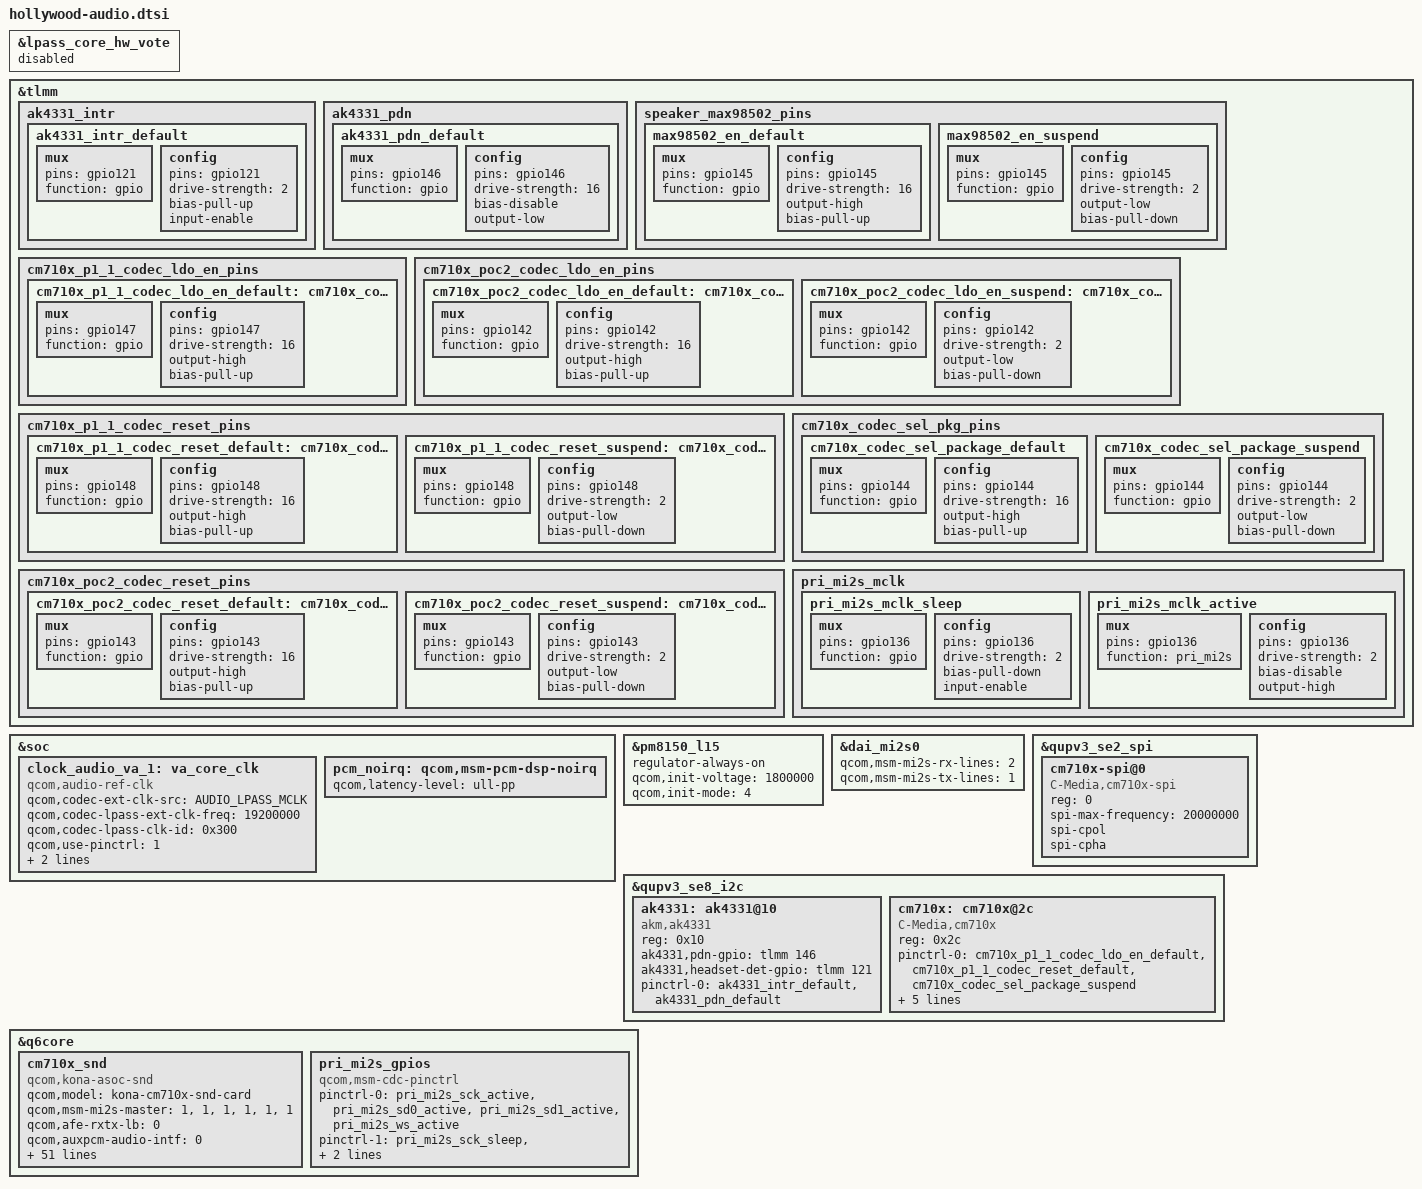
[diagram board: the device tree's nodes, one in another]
#include <dt-bindings/clock/qcom,audio-ext-clk.h>

&lpass_core_hw_vote {
	status = "disabled";
};

&tlmm {
	ak4331_intr {
		ak4331_intr_default: ak4331_intr_default {
			 mux {
				pins = "gpio121";
				function = "gpio";
			};

			config {
				pins = "gpio121";
				drive-strength = <2>; /* 2 mA */
				bias-pull-up; /* pull up */
				input-enable;
			};
		};
	};

	ak4331_pdn {
		ak4331_pdn_default: ak4331_pdn_default {
			 mux {
				pins = "gpio146";
				function = "gpio";
			};

			config {
				pins = "gpio146";
				drive-strength = <16>; /* 16 mA */
				bias-disable; /* no pull */
				output-low;
			};
		};
	};

	speaker_max98502_pins {
		max98502_en_default: max98502_en_default {
			mux {
				pins = "gpio145";
				function = "gpio";
			};

			config {
				pins = "gpio145";
				drive-strength = <16>;
				output-high;
				bias-pull-up;
			};
		};
		max98502_en_suspend: max98502_en_suspend {
			mux {
				pins = "gpio145";
				function = "gpio";
			};

			config {
				pins = "gpio145";
				drive-strength = <2>;
				output-low;
				bias-pull-down;
			};
		};
	};

	cm710x_p1_1_codec_ldo_en_pins {
		cm710x_p1_1_codec_ldo_en_default: cm710x_codec_ldo_en_default {
			mux {
				pins = "gpio147";
				function = "gpio";
			};

			config {
				pins = "gpio147";
				drive-strength = <16>;
				output-high;
				bias-pull-up;
			};
		};
	};

	cm710x_poc2_codec_ldo_en_pins {
		cm710x_poc2_codec_ldo_en_default: cm710x_codec_ldo_en_default {
			mux {
				pins = "gpio142";
				function = "gpio";
			};

			config {
				pins = "gpio142";
				drive-strength = <16>;
				output-high;
				bias-pull-up;
			};
		};
		cm710x_poc2_codec_ldo_en_suspend: cm710x_codec_ldo_en_suspend {
			mux {
				pins = "gpio142";
				function = "gpio";
			};

			config {
				pins = "gpio142";
				drive-strength = <2>;
				output-low;
				bias-pull-down;
			};
		};
	};

	cm710x_p1_1_codec_reset_pins {
		cm710x_p1_1_codec_reset_default: cm710x_codec_reset_default {
			mux {
				pins = "gpio148";
				function = "gpio";
			};

			config {
				pins = "gpio148";
				drive-strength = <16>;
				output-high;
				bias-pull-up;
			};
		};
		cm710x_p1_1_codec_reset_suspend: cm710x_codec_reset_suspend {
			mux {
				pins = "gpio148";
				function = "gpio";
			};

			config {
				pins = "gpio148";
				drive-strength = <2>;
				output-low;
				bias-pull-down;
			};
		};
	};

	cm710x_poc2_codec_reset_pins {
		cm710x_poc2_codec_reset_default: cm710x_codec_reset_default {
			mux {
				pins = "gpio143";
				function = "gpio";
			};

			config {
				pins = "gpio143";
				drive-strength = <16>;
				output-high;
				bias-pull-up;
			};
		};
		cm710x_poc2_codec_reset_suspend: cm710x_codec_reset_suspend {
			mux {
				pins = "gpio143";
				function = "gpio";
			};

			config {
				pins = "gpio143";
				drive-strength = <2>;
				output-low;
				bias-pull-down;
			};
		};
	};

	cm710x_codec_sel_pkg_pins {
		cm710x_codec_sel_package_default: cm710x_codec_sel_package_default {
			mux {
				pins = "gpio144";
				function = "gpio";
			};

			config {
				pins = "gpio144";
				drive-strength = <16>;
				output-high;
				bias-pull-up;
			};
		};
		cm710x_codec_sel_package_suspend: cm710x_codec_sel_package_suspend {
			mux {
				pins = "gpio144";
				function = "gpio";
			};

			config {
				pins = "gpio144";
				drive-strength = <2>;
				output-low;
				bias-pull-down;
			};
		};
	};

	pri_mi2s_mclk {
		pri_mi2s_mclk_sleep: pri_mi2s_mclk_sleep {
			mux {
				pins = "gpio136";
				function = "gpio";
			};

			config {
				pins = "gpio136";
				drive-strength = <2>;   /* 2 mA */
				bias-pull-down;         /* PULL DOWN */
				input-enable;
			};
		};

		pri_mi2s_mclk_active: pri_mi2s_mclk_active {
			mux {
				pins = "gpio136";
				function = "pri_mi2s";
			};

			config {
				pins = "gpio136";
				drive-strength = <2>;   /* 2 mA */
				bias-disable;           /* NO PULL */
				output-high;
			};
		};
	};
};

&soc {
	clock_audio_va_1: va_core_clk {
		status = "ok";
		compatible = "qcom,audio-ref-clk";
		qcom,codec-ext-clk-src = <AUDIO_LPASS_MCLK>;
		qcom,codec-lpass-ext-clk-freq = <19200000>;
		qcom,codec-lpass-clk-id = <0x300>;
		#clock-cells = <1>;
		qcom,use-pinctrl = <1>;
		pinctrl-names = "active", "sleep";
		pinctrl-0 = <&pri_mi2s_mclk_active>;
		pinctrl-1 = <&pri_mi2s_mclk_sleep>;
	};

	pcm_noirq: qcom,msm-pcm-dsp-noirq {
		qcom,latency-level = "ull-pp";
	};
};

&pm8150_l15 {
	regulator-always-on;
	qcom,init-voltage = <1800000>;
	qcom,init-mode = <4>; /* RPMH_REGULATOR_MODE_HPM */
};

&dai_mi2s0 {
	qcom,msm-mi2s-rx-lines = <2>;
	qcom,msm-mi2s-tx-lines = <1>;
};

&qupv3_se2_spi {
	status = "okay";

	cm710x-spi@0 {
		status = "okay";
		compatible = "C-Media,cm710x-spi";
		reg = <0>;
		spi-max-frequency = <20000000>;
		spi-cpol;
		spi-cpha;
	};
};

&qupv3_se8_i2c {
	status = "ok";

	ak4331: ak4331@10 {
		status = "ok";
		compatible = "akm,ak4331";
		reg = <0x10>;

		ak4331,pdn-gpio = <&tlmm 146 0>;
		ak4331,headset-det-gpio = <&tlmm 121 0>;
		pinctrl-names = "default";
		pinctrl-0 = <&ak4331_intr_default &ak4331_pdn_default>;

	};

	cm710x: cm710x@2c {
		status = "ok";
		compatible = "C-Media,cm710x";
		reg = <0x2c>;

		pinctrl-names = "cm710x_codec_default", "cm710x_codec_suspend",
			"cm710x_codec_spk_en", "cm710x_codec_spk_suspend";
		pinctrl-0 = <&cm710x_p1_1_codec_ldo_en_default
			&cm710x_p1_1_codec_reset_default
			&cm710x_codec_sel_package_suspend>;
		pinctrl-1 = <&cm710x_p1_1_codec_reset_suspend>;
		pinctrl-2 = <&max98502_en_default>;
		pinctrl-3 = <&max98502_en_suspend>;

		clock-names = "cm7104_mclk";
		clocks = <&clock_audio_va_1 0>;

		cm710x,fw-parsing = "spi";
	};
};

&q6core {
	cm710x_snd: cm710x_snd {
		compatible = "qcom,kona-asoc-snd";
		qcom,model = "kona-cm710x-snd-card";

		qcom,msm-mi2s-master = <1>, <1>, <1>, <1>, <1>, <1>;

		qcom,afe-rxtx-lb = <0>;
		qcom,auxpcm-audio-intf = <0>;
		qcom,ext-disp-audio-rx = <0>;
		qcom,mi2s-audio-intf = <1>;
		qcom,tdm-audio-intf = <0>;
		qcom,wcn-bt = <0>;
		qcom,msm_audio_ssr_devs = <&audio_apr>, <&q6core>;
		qcom,audio-routing =
			"AIF4 VI", "MCLK",
			"MADINPUT", "MCLK",
			"LDO_RXTX", "MCLK";
		clock-names = "lpass_audio_hw_vote";
		clocks = <&lpass_audio_hw_vote 0>;

		asoc-codec = <&stub_codec>, <&cm710x>;
		asoc-codec-names = "msm-stub-codec.1", "cm710x_codec";

		asoc-platform = <&pcm0>, <&pcm1>, <&pcm2>, <&voip>, <&voice>,
				<&loopback>, <&compress>, <&hostless>,
				<&afe>, <&lsm>, <&routing>, <&compr>,
				<&pcm_noirq>;
		asoc-platform-names = "msm-pcm-dsp.0", "msm-pcm-dsp.1",
				"msm-pcm-dsp.2", "msm-voip-dsp",
				"msm-pcm-voice", "msm-pcm-loopback",
				"msm-compress-dsp", "msm-pcm-hostless",
				"msm-pcm-afe", "msm-lsm-client",
				"msm-pcm-routing", "msm-compr-dsp",
				"msm-pcm-dsp-noirq";
		asoc-cpu = <&dai_mi2s0>, <&dai_mi2s1>,
				<&dai_mi2s2>, <&dai_mi2s3>,
				<&dai_mi2s4>, <&dai_mi2s5>,
				<&afe_pcm_rx>, <&afe_pcm_tx>, <&afe_proxy_rx>,
				<&afe_proxy_tx>, <&incall_record_rx>,
				<&incall_record_tx>, <&incall_music_rx>,
				<&incall_music_2_rx>,
				<&usb_audio_rx>, <&usb_audio_tx>,
				<&sb_7_rx>, <&sb_7_tx>,
				<&dai_pri_tdm_rx_0>, <&dai_pri_tdm_tx_0>,
				<&dai_sec_tdm_rx_0>, <&dai_sec_tdm_tx_0>,
				<&dai_tert_tdm_rx_0>, <&dai_tert_tdm_tx_0>,
				<&dai_quat_tdm_rx_0>, <&dai_quat_tdm_tx_0>,
				<&dai_quin_tdm_rx_0>, <&dai_quin_tdm_tx_0>,
				<&dai_sen_tdm_rx_0>, <&dai_sen_tdm_tx_0>,
				<&afe_loopback_tx>;
		asoc-cpu-names = "msm-dai-q6-mi2s.0", "msm-dai-q6-mi2s.1",
				"msm-dai-q6-mi2s.2", "msm-dai-q6-mi2s.3",
				"msm-dai-q6-mi2s.4", "msm-dai-q6-mi2s.5",
				"msm-dai-q6-dev.224",
				"msm-dai-q6-dev.225", "msm-dai-q6-dev.241",
				"msm-dai-q6-dev.240", "msm-dai-q6-dev.32771",
				"msm-dai-q6-dev.32772", "msm-dai-q6-dev.32773",
				"msm-dai-q6-dev.32770",
				"msm-dai-q6-dev.28672", "msm-dai-q6-dev.28673",
				"msm-dai-q6-dev.16398", "msm-dai-q6-dev.16399",
				"msm-dai-q6-tdm.36864", "msm-dai-q6-tdm.36865",
				"msm-dai-q6-tdm.36880", "msm-dai-q6-tdm.36881",
				"msm-dai-q6-tdm.36896", "msm-dai-q6-tdm.36897",
				"msm-dai-q6-tdm.36912", "msm-dai-q6-tdm.36913",
				"msm-dai-q6-tdm.36928", "msm-dai-q6-tdm.36929",
				"msm-dai-q6-tdm.36944", "msm-dai-q6-tdm.36945",
				"msm-dai-q6-dev.24577";

		qcom,pri-mi2s-gpios = <&pri_mi2s_gpios>;
	};

	pri_mi2s_gpios: pri_mi2s_gpios {
		compatible = "qcom,msm-cdc-pinctrl";
		pinctrl-names = "aud_active", "aud_sleep";
		pinctrl-0 = <&pri_mi2s_sck_active
			&pri_mi2s_sd0_active &pri_mi2s_sd1_active &pri_mi2s_ws_active>;
		pinctrl-1 = <&pri_mi2s_sck_sleep
			&pri_mi2s_sd0_sleep &pri_mi2s_sd1_sleep &pri_mi2s_ws_sleep>;
	};
};
